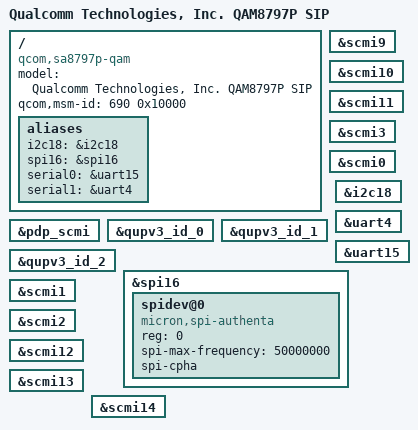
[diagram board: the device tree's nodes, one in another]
// SPDX-License-Identifier: BSD-3-Clause
/*
 * Copyright (c) 2024 Qualcomm Innovation Center, Inc. All rights reserved.
 */

/ {
	model = "Qualcomm Technologies, Inc. QAM8797P SIP";
	compatible = "qcom,sa8797p-qam","qcom,sa8797p";
	qcom,msm-id = <690 0x10000>;

	aliases {
		i2c18 = &i2c18;
		spi16 = &spi16;
		serial0 = &uart15;
		serial1 = &uart4;
	};
};

&scmi9 {
	status = "okay";
};

&scmi10 {
	status = "okay";
};

&scmi11 {
	status = "okay";
};

&pdp_scmi {
	status = "okay";
};

&scmi3 {
	status = "okay";
};

&scmi0 {
	status = "okay";
};

&qupv3_id_0 {
	status = "okay";
};

&qupv3_id_1 {
	status = "okay";
};

&qupv3_id_2 {
	status = "okay";
};

&i2c18 {
	status = "okay";
};

&uart4 {
	status = "okay";
};

&uart15 {
	status = "okay";
};

&spi16 {
	status = "okay";
	spidev@0 {
		compatible = "micron,spi-authenta";
		reg = <0>;
		spi-max-frequency = <50000000>;
		spi-cpha;
	};
};

&scmi1 {
	status = "okay";
};

&scmi2 {
	status = "okay";
};

&scmi12 {
	status = "okay";
};

&scmi13 {
	status = "okay";
};

&scmi14 {
	status = "okay";
};
